# AST1060 register map
File version: 1.0
CPU: CM4 r0p1, little endian, MPU, FPU, 4 interrupt priority bits, 256 interrupts
Registers are 32-bit, read-write, reset 0x0 unless marked. A register's access mark holds for its fields unless they carry their own. Offsets are from the block's base; [hi:lo] are bit positions; {n}, {i} and the like mark numbered series.

## scu
Base 0x7E6E2000
0x00 SCU000 — Protection Key Register
  [31:0] ProtKey — Protection Key
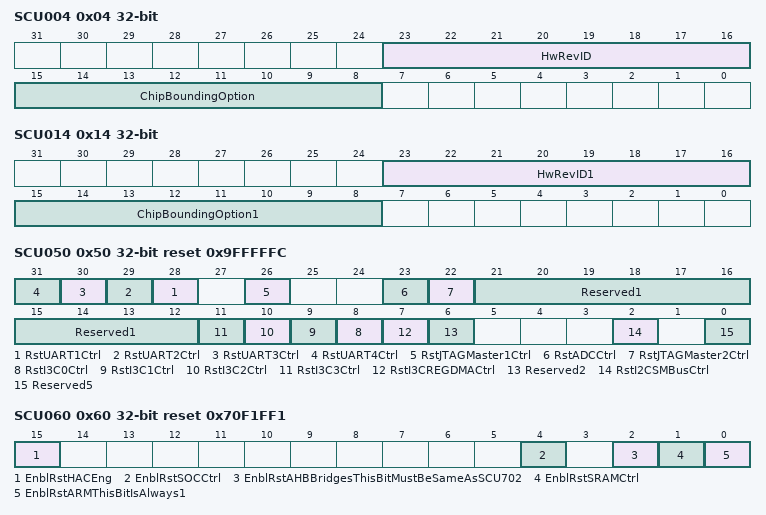
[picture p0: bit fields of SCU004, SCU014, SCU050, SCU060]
0x04 SCU004 — Silicon Revision ID Register
  [23:16] HwRevID ro — Hardware Revision ID
  [15:8] ChipBoundingOption ro
0x10 SCU010 — Protection Key Register 2
  [31:0] ThisRegIsDesignedToProtectSCURegFromUnpredictableUpdates — This register is designed to protect SCU registers from unpredictable updates,
0x14 SCU014 — Silicon Revision ID Register
  [23:16] HwRevID1 ro — Hardware Revision ID
  [15:8] ChipBoundingOption1 ro — Chip bounding option
0x40 SCU040 reset 0xFFC3FED8 — System Reset Control Register
  [0] EnblRstSRAMCtrlWhenFullChipWDResetOccur — Enable reset SRAM controller when full chip Watchdog reset occur
0x44 SCU044 — System Reset Control Clear Register 2
  [31:0] SCU040SysRstCtrlClearReg — SCU040 System Reset Control Clear Register
0x50 SCU050 reset 0x9FFFFFC (reset mask 0xFCC00F84) — System Reset Control Register Set 2
  [n+27] RstUART{n}Ctrl (n=1..4) — Reset UART{n} controller
  [26] RstJTAGMaster1Ctrl — Reset JTAG Master 1 controller
  [23] RstADCCtrl — Reset ADC controller
  [22] RstJTAGMaster2Ctrl — Reset JTAG Master 2 controller
  [21:12] Reserved1 — Reserved, must keep at value all "1"
  [n+8] RstI3C{n}Ctrl (n=0..3) — Reset I3C{n} controller
  [7] RstI3CREGDMACtrl — Reset I3C REG/DMA controller
  [6] Reserved2 — Reserved, must keep at value "1"
  [2] RstI2CSMBusCtrl — Reset I2C/SMBus controller
  [0] Reserved5 — Reserved, must keep at value "1"
0x54 SCU054 — System Reset Control Clear Register 2
  [31:0] SCU050SysRstCtrlClearReg2 — SCU050 System Reset Control Clear Register 2
0x60 SCU060 reset 0x70F1FF1 — EXTRST\# Reset Selection
  [15] EnblRstHACEng — Enable reset HAC engine
  [4] EnblRstSOCCtrl — Enable reset SOC controller
  [2] EnblRstAHBBridgesThisBitMustBeSameAsSCU702 — Enable reset AHB bridges. This bit must be same as SCU70[2].
  [1] EnblRstSRAMCtrl — Enable reset SRAM controller
  [0] EnblRstARMThisBitIsAlways1 ro — Enable reset ARM. This bit is always 1.
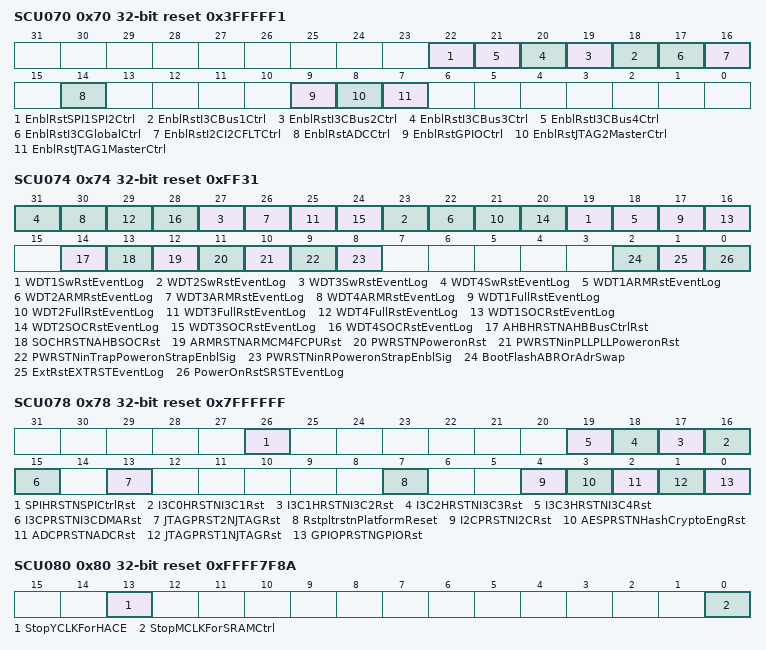
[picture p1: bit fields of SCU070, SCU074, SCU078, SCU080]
0x70 SCU070 reset 0x3FFFFF1 — EXTRST\# Reset Selection
  [22] EnblRstSPI1SPI2Ctrl — Enable reset SPI1/SPI2 controller
  [n+17] EnblRstI3CBus{n}Ctrl (n=1..4) — Enable reset I3C bus{n} controller
  [17] EnblRstI3CGlobalCtrl — Enable reset I3C Global controller
  [16] EnblRstI2CI2CFLTCtrl — Enable reset I2C/I2CFLT controller
  [14] EnblRstADCCtrl — Enable reset ADC controller
  [9] EnblRstGPIOCtrl — Enable reset GPIO controller
  [8] EnblRstJTAG2MasterCtrl — Enable reset JTAG #2 master controller
  [7] EnblRstJTAG1MasterCtrl — Enable reset JTAG #1 master controller
0x74 SCU074 reset 0xFF31 — System Reset Event Log Register Set 2-1
  [4n+15] WDT{n}SwRstEventLog (n=1..4) — WDT{n} Software Reset event log
  [4n+14] WDT{n}ARMRstEventLog (n=1..4) — WDT{n} ARM Reset event log
  [4n+13] WDT{n}FullRstEventLog (n=1..4) — WDT{n} Full Reset event log
  [4n+12] WDT{n}SOCRstEventLog (n=1..4) — WDT{n} SOC Reset event log
  [14] AHBHRSTNAHBBusCtrlRst — Reset event log -- AHB_HRST_N AHB Bus Controller reset
  [13] SOCHRSTNAHBSOCRst — Reset event log -- SOC_HRST_N AHB SOC reset
  [12] ARMRSTNARMCM4FCPURst — Reset event log -- ARMRST_N ARM CM4F CPU reset
  [11] PWRSTNPoweronRst — Reset event log -- PWRST_N Power-on reset
  [10] PWRSTNinPLLPLLPoweronRst — Reset event log -- PWRSTNinPLL PLL power-on reset
  [9] PWRSTNinTrapPoweronStrapEnblSig — Reset event log -- PWRSTNinTrap Power-on strap enable signal
  [8] PWRSTNinRPoweronStrapEnblSig — Reset event log -- PWRSTNinR Power-on strap enable signal
  [2] BootFlashABROrAdrSwap — Boot flash reset event log -- ABR or AdrSwap
  [1] ExtRstEXTRSTEventLog — External reset EXTRST# event log
  [0] PowerOnRstSRSTEventLog — Power on reset SRST# event log
0x78 SCU078 reset 0x7FFFFFF — System Reset Event Log Register Set 2-2
  [26] SPIHRSTNSPICtrlRst — Reset event log -- SPI_HRST_N SPI Controller reset
  [n+16] I3C{n}HRSTNI3C{n+1}Rst (n=0..3) — Reset event log -- I3C{n}_HRST_N I3C #{n+1} reset
  [15] I3CPRSTNI3CDMARst — Reset event log -- I3C_PRST_N I3C DMA reset
  [13] JTAGPRST2NJTAGRst — Reset event log -- JTAG_PRST#2_N JTAG reset
  [7] RstpltrstnPlatformReset — Reset event log -- rstpltrstn Platform Reset
  [4] I2CPRSTNI2CRst — Reset event log -- I2C_PRST_N I2C reset
  [3] AESPRSTNHashCryptoEngRst — Reset event log -- AES_PRST_N Hash crypto engine reset
  [2] ADCPRSTNADCRst — Reset event log -- ADC_PRST_N ADC reset
  [1] JTAGPRST1NJTAGRst — Reset event log -- JTAG_PRST#1_N JTAG reset
  [0] GPIOPRSTNGPIORst — Reset event log -- GPIO_PRST_N GPIO reset
0x80 SCU080 reset 0xFFFF7F8A — Clock Stop Control Register
  [13] StopYCLKForHACE
  [0] StopMCLKForSRAMCtrl — Stop MCLK (For SRAM Controller)
0x84 SCU084 — Clock Stop Control Clear Register
  [31:0] SCU080ClkStopCtrlClearReg — SCU080 Clock Stop Control Clear Register
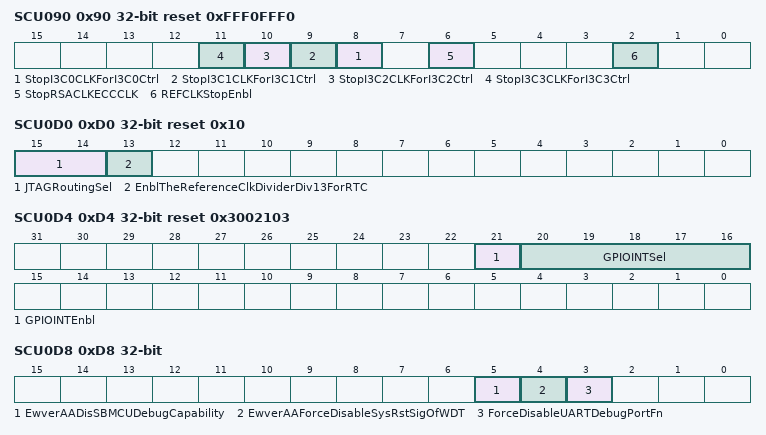
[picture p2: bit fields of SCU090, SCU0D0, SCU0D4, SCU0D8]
0x90 SCU090 reset 0xFFF0FFF0 — Clock Stop Control Register Set 2
  [n+8] StopI3C{n}CLKForI3C{n}Ctrl (n=0..3) — Stop I3C{n}CLK (for I3C{n} Controller)
  [6] StopRSACLKECCCLK
  [2] REFCLKStopEnbl — REFCLK Stop Enable
0x94 SCU094 — Clock Stop Control Clear Register Set 2
  [31:0] SCU090ClkStopCtrlClearRegSet2 — SCU090 Clock Stop Control Clear Register Set 2
0xD0 SCU0D0 reset 0x10 — Misc. 3 Control Register\label{SCUREG:MISC3
  [15:14] JTAGRoutingSel — JTAG routing selection
  [13] EnblTheReferenceClkDividerDiv13ForRTC — Enable the reference clock divider (div13) for RTC
0xD4 SCU0D4 reset 0x3002103 — Misc. 4 Control Register\label{SCUREG:MISC4
  [21] GPIOINTEnbl — GPIO Interrupt Enable
  [20:16] GPIOINTSel — GPIO Interrupt Selection
0xD8 SCU0D8 — Debug Control Register 2
  [5] EwverAADisSBMCUDebugCapability — ewverAADisable SBMCU debug capability
  [4] EwverAAForceDisableSysRstSigOfWDT — ewverAAForce disable system reset signal of WDT
  [3] ForceDisableUARTDebugPortFn — Force disable UART debug port function
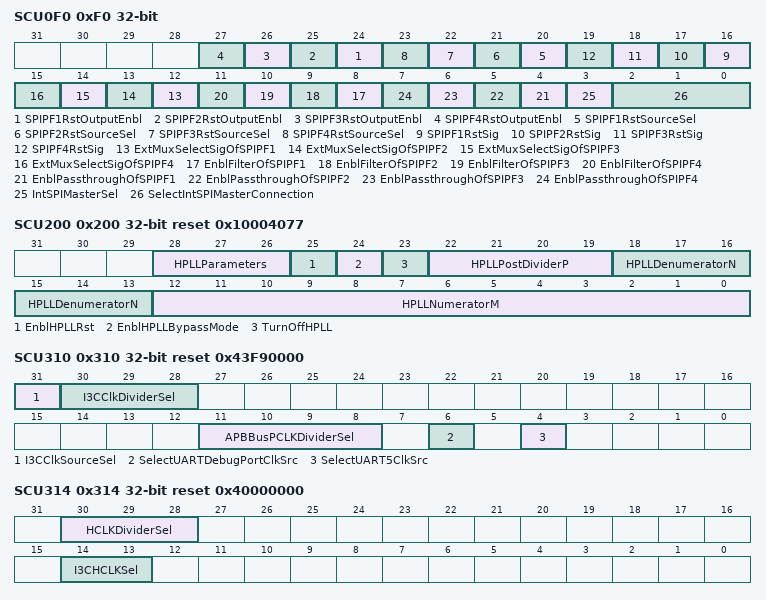
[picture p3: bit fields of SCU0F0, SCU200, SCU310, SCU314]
0xF0 SCU0F0 — QSPI Monitor Internal Mux Register
  [n+23] SPIPF{n}RstOutputEnbl (n=1..4) — SPI_PF{n} Reset Output Enable
  [n+19] SPIPF{n}RstSourceSel (n=1..4) — SPI_PF{n} Reset Source Selection
  [n+15] SPIPF{n}RstSig (n=1..4) — SPI_PF{n} Reset Signal
  [n+11] ExtMuxSelectSigOfSPIPF{n} (n=1..4) — External Mux Select Signal of SPI_PF{n}
  [n+7] EnblFilterOfSPIPF{n} (n=1..4) — Enable filter of SPI_PF{n}
  [n+3] EnblPassthroughOfSPIPF{n} (n=1..4) — Enable passthrough of SPI_PF{n}
  [3] IntSPIMasterSel — Internal SPI master selection
  [2:0] SelectIntSPIMasterConnection — Select internal SPI master connection
0x200 SCU200 reset 0x10004077 — H-PLL Parameter Register
  [28:26] HPLLParameters
  [25] EnblHPLLRst — Enable H-PLL reset
  [24] EnblHPLLBypassMode — Enable H-PLL bypass mode
  [23] TurnOffHPLL
  [22:19] HPLLPostDividerP
  [18:13] HPLLDenumeratorN
  [12:0] HPLLNumeratorM
0x204 SCU204 reset 0x31 — Extended H-PLL Parameter Register
  [11:0] HPLLBandwidthAdjustmentBit15 — 10]
0x310 SCU310 reset 0x43F90000 — Clock Selection Register Set 4
  [31] I3CClkSourceSel — I3C Clock Source selection
  [30:28] I3CClkDividerSel — I3C Clock divider selection
  [11:8] APBBusPCLKDividerSel — APB Bus PCLK divider selection
  [6] SelectUARTDebugPortClkSrc — Select UART debug port clock source
  [4] SelectUART5ClkSrc — Select UART5 clock source
0x314 SCU314 reset 0x40000000 — Clock Selection Register Set 5
  [30:28] HCLKDividerSel — HCLK divider selection
  [14:13] I3CHCLKSel — I3CHCLK selection
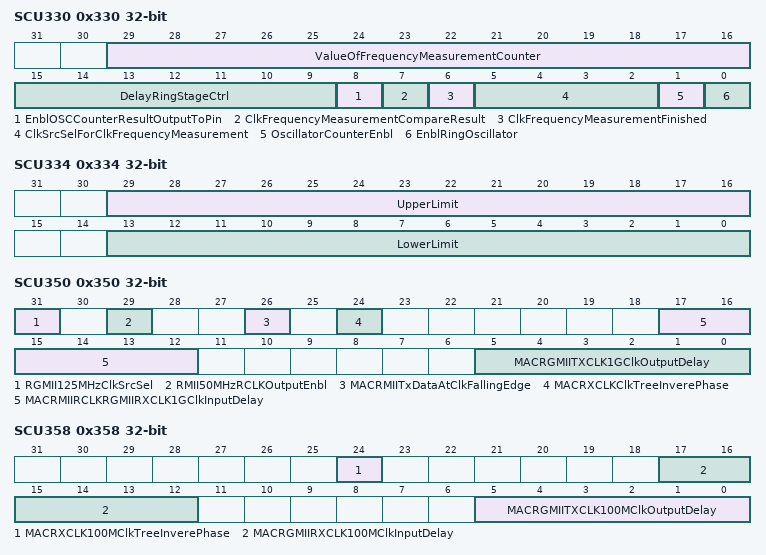
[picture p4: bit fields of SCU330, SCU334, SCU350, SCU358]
0x330 SCU330 — Frequency Counter Control Register
  [29:16] ValueOfFrequencyMeasurementCounter ro
  [15:9] DelayRingStageCtrl — Delay ring stage control
  [8] EnblOSCCounterResultOutputToPin — Enable OSC counter result output to pin
  [7] ClkFrequencyMeasurementCompareResult ro — Clock frequency measurement compare result
  [6] ClkFrequencyMeasurementFinished ro — Clock frequency measurement finished
  [5:2] ClkSrcSelForClkFrequencyMeasurement — Clock source selection for clock frequency measurement
  [1] OscillatorCounterEnbl — Oscillator Counter Enable
  [0] EnblRingOscillator — Enable Ring Oscillator
0x334 SCU334 — Frequency counter comparison range
  [29:16] UpperLimit, [13:0] LowerLimit
0x350 SCU350 — MAC Interface Clock Delay Setting
  [31] RGMII125MHzClkSrcSel — RGMII 125MHz clock source selection
  [29] RMII50MHzRCLKOutputEnbl — RMII 50MHz RCLK output enable
  [26] MACRMIITxDataAtClkFallingEdge — MAC RMII transmit data at clock falling edge
  [24] MACRXCLKClkTreeInverePhase — MAC RXCLK clock tree invere phase
  [17:12] MACRMIIRCLKRGMIIRXCLK1GClkInputDelay — MAC RMII_RCLK/RGMII_RXCLK (1G) clock input delay
  [5:0] MACRGMIITXCLK1GClkOutputDelay — MAC RGMII_TXCLK (1G) clock output delay
0x358 SCU358 — MAC Interface Clock Delay 100M Setting
  [24] MACRXCLK100MClkTreeInverePhase — MAC RXCLK 100M clock tree invere phase
  [17:12] MACRGMIIRXCLK100MClkInputDelay — MAC RGMII_RXCLK 100M clock input delay
  [5:0] MACRGMIITXCLK100MClkOutputDelay — MAC RGMII_TXCLK 100M clock output delay
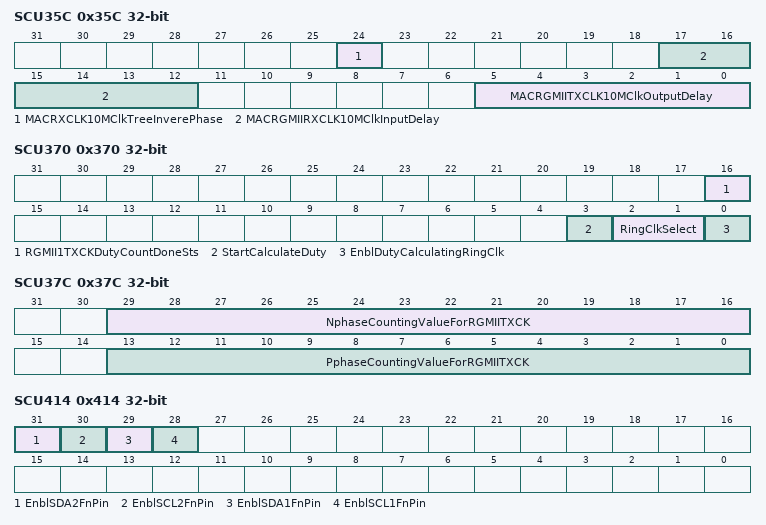
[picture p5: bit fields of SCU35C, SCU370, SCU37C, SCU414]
0x35C SCU35C — MAC Interface Clock Delay 10M Setting
  [24] MACRXCLK10MClkTreeInverePhase — MAC RXCLK 10M clock tree invere phase
  [17:12] MACRGMIIRXCLK10MClkInputDelay — MAC RGMII_RXCLK 10M clock input delay
  [5:0] MACRGMIITXCLK10MClkOutputDelay — MAC RGMII_TXCLK 10M clock output delay
0x370 SCU370 — Clock Duty Measurement Control
  [16] RGMII1TXCKDutyCountDoneSts ro — RGMII1TXCK Duty count done status
  [3] StartCalculateDuty
  [2:1] RingClkSelect — Ring clock select
  [0] EnblDutyCalculatingRingClk — Enable duty calculating ring clock
0x37C SCU37C — Clock Duty Measurement Result 2
  [29:16] NphaseCountingValueForRGMIITXCK ro, [13:0] PphaseCountingValueForRGMIITXCK ro
0x410 SCU410 reset not defined — Multi-function Pin Control \#1
0x414 SCU414 — Multi-function Pin Control \#2
  [31] EnblSDA2FnPin — Enable SDA2 function pin
  [30] EnblSCL2FnPin — Enable SCL2 function pin
  [29] EnblSDA1FnPin — Enable SDA1 function pin
  [28] EnblSCL1FnPin — Enable SCL1 function pin
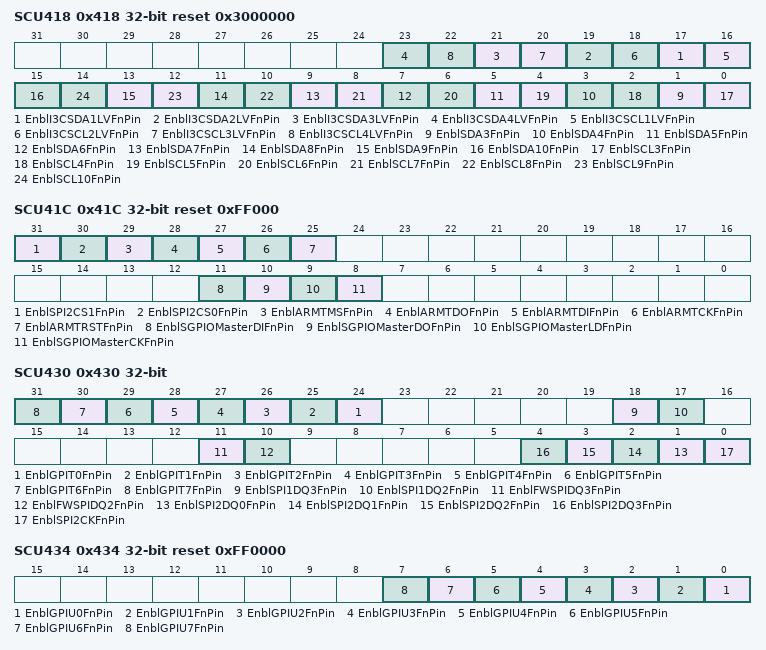
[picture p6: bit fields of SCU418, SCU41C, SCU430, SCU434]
0x418 SCU418 reset 0x3000000 — Multi-function Pin Control \#3
  [2n+15] EnblI3CSDA{n}LVFnPin (n=1..4) — Enable I3C SDA{n} LV function pin
  [2n+14] EnblI3CSCL{n}LVFnPin (n=1..4) — Enable I3C SCL{n} LV function pin
  [2n-5] EnblSDA{n}FnPin (n=3..10) — Enable SDA{n} function pin
  [2n-6] EnblSCL{n}FnPin (n=3..10) — Enable SCL{n} function pin
0x41C SCU41C reset 0xFF000 — Multi-function Pin Control \#4
  [31] EnblSPI2CS1FnPin — Enable SPI2CS1 function pin
  [30] EnblSPI2CS0FnPin — Enable SPI2CS0 function pin
  [29] EnblARMTMSFnPin — Enable ARM TMS function pin
  [28] EnblARMTDOFnPin — Enable ARM TDO function pin
  [27] EnblARMTDIFnPin — Enable ARM TDI function pin
  [26] EnblARMTCKFnPin — Enable ARM TCK function pin
  [25] EnblARMTRSTFnPin — Enable ARM TRST function pin
  [11] EnblSGPIOMasterDIFnPin — Enable SGPIO Master DI function pin
  [10] EnblSGPIOMasterDOFnPin — Enable SGPIO Master DO function pin
  [9] EnblSGPIOMasterLDFnPin — Enable SGPIO Master LD function pin
  [8] EnblSGPIOMasterCKFnPin — Enable SGPIO Master CK function pin
0x430 SCU430 — Multi-function Pin Control \#5
  [n+24] EnblGPIT{n}FnPin (n=0..7) — Enable GPIT{n} function pin
  [18] EnblSPI1DQ3FnPin — Enable SPI1DQ3 function pin
  [17] EnblSPI1DQ2FnPin — Enable SPI1DQ2 function pin
  [11] EnblFWSPIDQ3FnPin — Enable FWSPIDQ3 function pin
  [10] EnblFWSPIDQ2FnPin — Enable FWSPIDQ2 function pin
  [n+1] EnblSPI2DQ{n}FnPin (n=0..3) — Enable SPI2DQ{n} function pin
  [0] EnblSPI2CKFnPin — Enable SPI2CK function pin
0x434 SCU434 reset 0xFF0000 — Multi-function Pin Control \#6
  [n] EnblGPIU{n}FnPin (n=0..7) — Enable GPIU{n} function pin
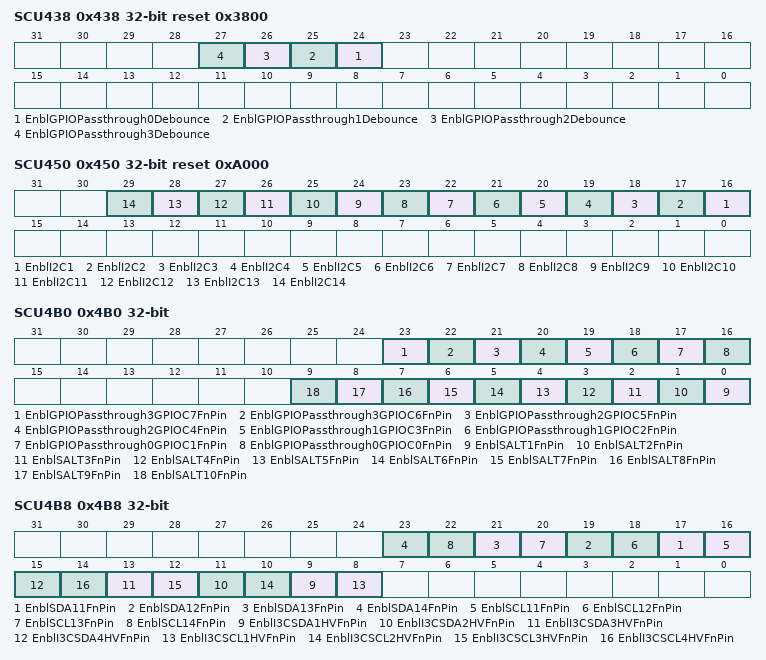
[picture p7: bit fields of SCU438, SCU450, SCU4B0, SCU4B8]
0x438 SCU438 reset 0x3800 — Multi-function Pin Control \#7
  [n+24] EnblGPIOPassthrough{n}Debounce (n=0..3) — Enable GPIO Passthrough {n} de-bounce
0x450 SCU450 reset 0xA000 — Multi-function Pin Control \#9
  [n+15] EnblI2C{n} (n=1..14) — Enable I2C{n}
0x454 SCU454 — Multi-function Pin Control \#10
  [20] EnblJTAGMasterRouting — Enable JTAG master routing
0x458 SCU458 reset 0x500 — Multi-function Pin Control \#11
  [20] VoltageOfGPION4N5N6N7O0O1O2O3
0x4B0 SCU4B0 — Multi-function Pin Control \#13
  [23] EnblGPIOPassthrough3GPIOC7FnPin — Enable GPIO Passthrough 3 (GPIOC7) function pin
  [22] EnblGPIOPassthrough3GPIOC6FnPin — Enable GPIO Passthrough 3 (GPIOC6) function pin
  [21] EnblGPIOPassthrough2GPIOC5FnPin — Enable GPIO Passthrough 2 (GPIOC5) function pin
  [20] EnblGPIOPassthrough2GPIOC4FnPin — Enable GPIO Passthrough 2 (GPIOC4) function pin
  [19] EnblGPIOPassthrough1GPIOC3FnPin — Enable GPIO Passthrough 1 (GPIOC3) function pin
  [18] EnblGPIOPassthrough1GPIOC2FnPin — Enable GPIO Passthrough 1 (GPIOC2) function pin
  [17] EnblGPIOPassthrough0GPIOC1FnPin — Enable GPIO Passthrough 0 (GPIOC1) function pin
  [16] EnblGPIOPassthrough0GPIOC0FnPin — Enable GPIO Passthrough 0 (GPIOC0) function pin
  [n-1] EnblSALT{n}FnPin (n=1..10) — Enable SALT{n} function pin
0x4B4 SCU4B4 reset not defined — Multi-function Pin Control \#14
0x4B8 SCU4B8 — Multi-function Pin Control \#15
  [2n-5] EnblSDA{n}FnPin (n=11..14) — Enable SDA{n} function pin
  [2n-6] EnblSCL{n}FnPin (n=11..14) — Enable SCL{n} function pin
  [2n+7] EnblI3CSDA{n}HVFnPin (n=1..4) — Enable I3C SDA{n} HV function pin
  [2n+6] EnblI3CSCL{n}HVFnPin (n=1..4) — Enable I3C SCL{n} HV function pin
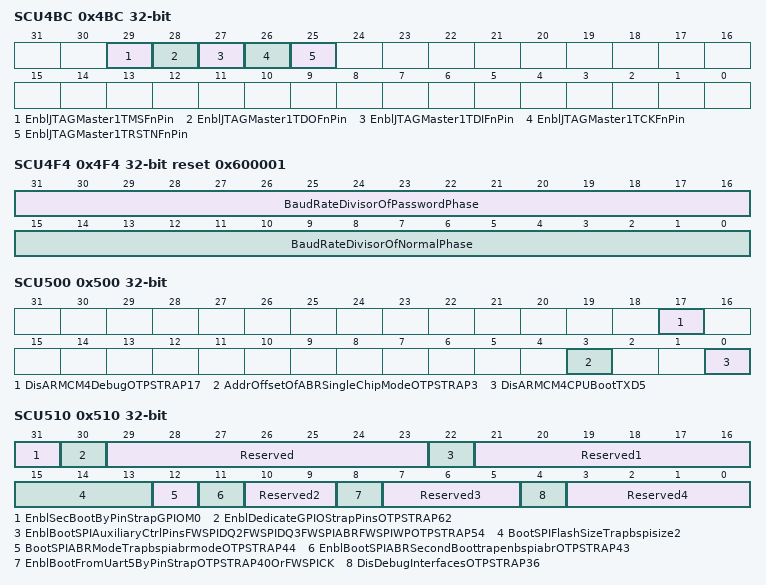
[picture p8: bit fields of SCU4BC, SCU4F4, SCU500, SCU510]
0x4BC SCU4BC — Multi-function Pin Control \#16
  [29] EnblJTAGMaster1TMSFnPin — Enable JTAG Master #1 TMS function pin
  [28] EnblJTAGMaster1TDOFnPin — Enable JTAG Master #1 TDO function pin
  [27] EnblJTAGMaster1TDIFnPin — Enable JTAG Master #1 TDI function pin
  [26] EnblJTAGMaster1TCKFnPin — Enable JTAG Master #1 TCK function pin
  [25] EnblJTAGMaster1TRSTNFnPin — Enable JTAG Master #1 TRSTN function pin
0x4D4 SCU4D4 reset not defined — Multi-function Pin Control \#18
0x4D8 SCU4D8 reset not defined — Multi-function Pin Control \#19
0x4F4 SCU4F4 reset 0x600001 — UART Debug interface Baud Rate Control
  [31:16] BaudRateDivisorOfPasswordPhase, [15:0] BaudRateDivisorOfNormalPhase
0x500 SCU500 — Hardware Strap1 Register\label{SCUREG:HWTRAPL
  [17] DisARMCM4DebugOTPSTRAP17 — Disable ARM CM4 debug (hlinkOTPSTRAP[17])
  [3] AddrOffsetOfABRSingleChipModeOTPSTRAP3 — Address Offset of ABR Single Chip Mode(hlinkOTPSTRAP[3])
  [0] DisARMCM4CPUBootTXD5 — Disable ARM CM4 CPU boot (TXD5)
0x504 SCU504 — Hardware Strap1 Clear Register
  [31:0] SCU500HwStrap1ClearReg — SCU500 Hardware Strap1 Clear Register
0x508 SCU508 reset 0x40080000 — Hardware Strap1 Protect Register
  [31:0] SCU500WrProtBitCtrl — SCU500 Write Protection Bit Control
0x510 SCU510 — Hardware Strap2 Register\label{SCUREG:HWTRAPH
  [31] EnblSecBootByPinStrapGPIOM0 — Enable Secure Boot by Pin Strap (GPIOM0)
  [30] EnblDedicateGPIOStrapPinsOTPSTRAP62 — Enable Dedicate GPIO Strap Pins (hlinkOTPSTRAP[62])
  [29:23] Reserved — 57])
  [22] EnblBootSPIAuxiliaryCtrlPinsFWSPIDQ2FWSPIDQ3FWSPIABRFWSPIWPOTPSTRAP54 — Enable boot SPI auxiliary control pins FWSPIDQ2, FWSPIDQ3, FWSPIABR#, FWSPIWP# (hlinkOTPSTRAP[54])
  [21:16] Reserved1 — 48])
  [15:13] BootSPIFlashSizeTrapbspisize2 — 0]) (hlinkOTPSTRAP[47:45], FWSPICK, GPION2,GPION0)
  [12] BootSPIABRModeTrapbspiabrmodeOTPSTRAP44 — Boot SPI ABR Mode (trap_bspi_abrmode) (hlinkOTPSTRAP[44])
  [11] EnblBootSPIABRSecondBoottrapenbspiabrOTPSTRAP43 — Enable boot SPI ABR (second boot)(trap_en_bspiabr) (hlinkOTPSTRAP[43])
  [10:9] Reserved2 — 41])
  [8] EnblBootFromUart5ByPinStrapOTPSTRAP40OrFWSPICK — Enable Boot from Uart5 by Pin Strap (hlinkOTPSTRAP[40] or FWSPICK)
  [7:5] Reserved3 — 37])
  [4] DisDebugInterfacesOTPSTRAP36 — Disable Debug Interfaces (hlinkOTPSTRAP[36])
  [3:0] Reserved4 — 32])
0x514 SCU514 — Hardware Strap2 Clear Register
  [31:0] SCU510HwStrap2ClearReg — SCU510 Hardware Strap2 Clear Register
0x518 SCU518 reset 0x10 — Hardware Strap2 Protect Register
  [31:0] SCU510WrProtBitCtrl — SCU510 Write Protection Bit Control
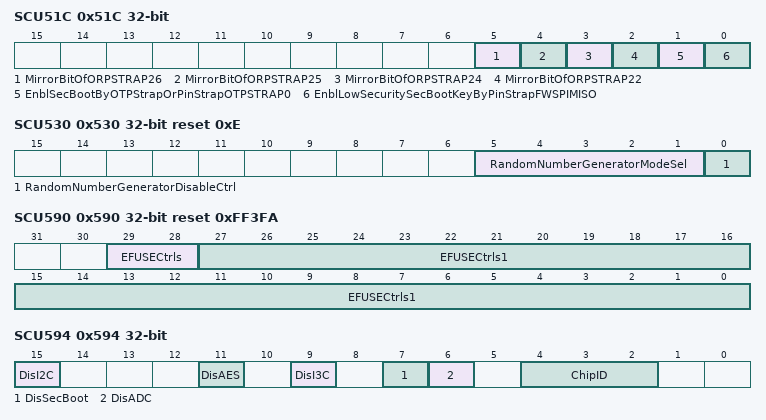
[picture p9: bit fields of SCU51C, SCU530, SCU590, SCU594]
0x51C SCU51C — Hardware Pin Strap Register\label{SCUREG:HWTRAPHRO
  [5] MirrorBitOfORPSTRAP26
  [4] MirrorBitOfORPSTRAP25
  [3] MirrorBitOfORPSTRAP24
  [2] MirrorBitOfORPSTRAP22
  [1] EnblSecBootByOTPStrapOrPinStrapOTPSTRAP0 — Enable Secure Boot by OTP Strap or Pin Strap (hlinkOTPSTRAP[0])
  [0] EnblLowSecuritySecBootKeyByPinStrapFWSPIMISO — Enable Low Security Secure Boot Key by Pin Strap (FWSPIMISO)
0x530 SCU530 reset 0xE — Random Number Generator 2 Control
  [5:1] RandomNumberGeneratorModeSel — Random number generator mode selection
  [0] RandomNumberGeneratorDisableCtrl — Random number generator disable control
0x534 SCU534 — Random Number Generator 2 Data Output
  [31:0] RandomNumberData ro
0x590 SCU590 reset 0xFF3FA — EFUSE Control
  [29:28] EFUSECtrls ro — EFUSE Controls
  [27:0] EFUSECtrls1 — EFUSE Controls
0x594 SCU594 — EFUSE Data Register
  [15] DisI2C ro — Disable I2C
  [11] DisAES ro — Disable AES
  [9] DisI3C ro — Disable I3C
  [7] DisSecBoot ro — Disable Secure Boot
  [6] DisADC ro — Disable ADC
  [4:2] ChipID ro
0x5B0 SCU5B0 — Chip Unique ID 0
  [31:0] ChipUniqueIDBit63 ro — 0] read back
0x5B4 SCU5B4 — Chip Unique ID 1
  [31:0] ChipUniqueIDBit631 ro — 0] read back
0x5B8 SCU5B8 — Reserved Read Only ID 0
  [31:0] Reserved ro — 0] read back
0x5BC SCU5BC — Reserved Read Only ID 1
  [31:0] Reserved1 ro — 0] read back
0x5D0 SCU5D0 — Reserved Read Only ID 2
  [31:0] Reserved2 ro — 0] read back
0x5D4 SCU5D4 — Reserved Read Only ID 3
  [31:0] Reserved3 ro — 0] read back
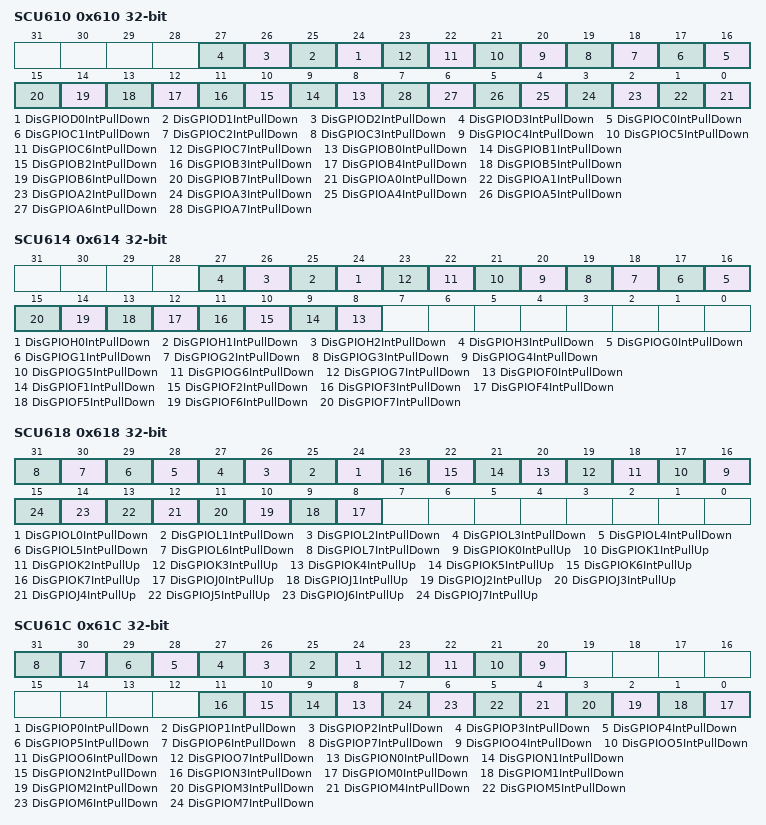
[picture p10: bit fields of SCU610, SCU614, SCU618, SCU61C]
0x610 SCU610 — Disable GPIO Internal Pull-Down \#0
  [n+24] DisGPIOD{n}IntPullDown (n=0..3) — Disable GPIOD{n} Internal Pull-Down
  [n+16] DisGPIOC{n}IntPullDown (n=0..7) — Disable GPIOC{n} Internal Pull-Down
  [n+8] DisGPIOB{n}IntPullDown (n=0..7) — Disable GPIOB{n} Internal Pull-Down
  [n] DisGPIOA{n}IntPullDown (n=0..7) — Disable GPIOA{n} Internal Pull-Down
0x614 SCU614 — Disable GPIO Internal Pull-Down \#1
  [n+24] DisGPIOH{n}IntPullDown (n=0..3) — Disable GPIOH{n} Internal Pull-Down
  [n+16] DisGPIOG{n}IntPullDown (n=0..7) — Disable GPIOG{n} Internal Pull-Down
  [n+8] DisGPIOF{n}IntPullDown (n=0..7) — Disable GPIOF{n} Internal Pull-Down
0x618 SCU618 — Disable GPIO Internal Pull-Down \#2
  [n+24] DisGPIOL{n}IntPullDown (n=0..7) — Disable GPIOL{n} Internal Pull-Down
  [n+16] DisGPIOK{n}IntPullUp (n=0..7) — Disable GPIOK{n} Internal Pull-Up
  [n+8] DisGPIOJ{n}IntPullUp (n=0..7) — Disable GPIOJ{n} Internal Pull-Up
0x61C SCU61C — Disable GPIO Internal Pull-Down \#3
  [n+24] DisGPIOP{n}IntPullDown (n=0..7) — Disable GPIOP{n} Internal Pull-Down
  [n+16] DisGPIOO{n}IntPullDown (n=4..7) — Disable GPIOO{n} Internal Pull-Down
  [n+8] DisGPION{n}IntPullDown (n=0..3) — Disable GPION{n} Internal Pull-Down
  [n] DisGPIOM{n}IntPullDown (n=0..7) — Disable GPIOM{n} Internal Pull-Down
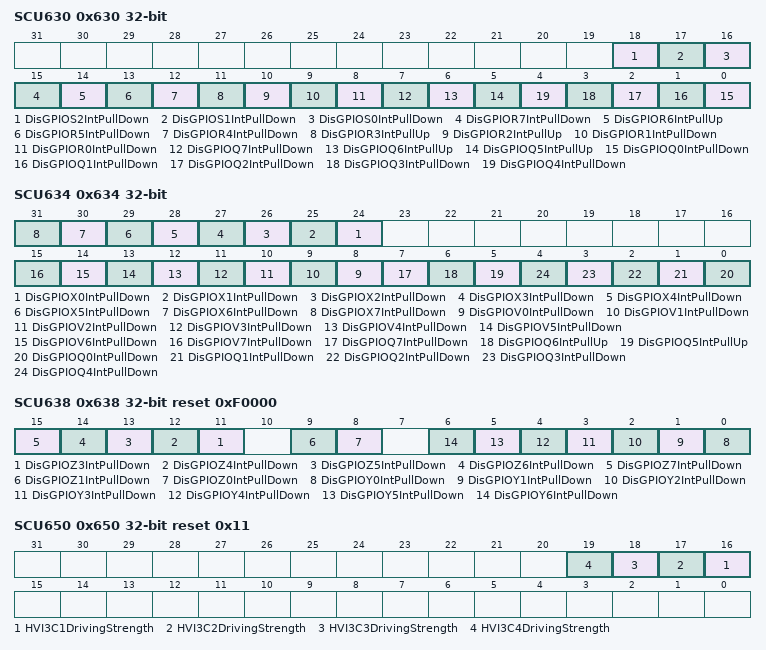
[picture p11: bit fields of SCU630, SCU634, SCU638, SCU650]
0x630 SCU630 — Disable GPIO Internal Pull-Down \#4
  [18] DisGPIOS2IntPullDown — Disable GPIOS2 Internal Pull-Down
  [17] DisGPIOS1IntPullDown — Disable GPIOS1 Internal Pull-Down
  [16] DisGPIOS0IntPullDown — Disable GPIOS0 Internal Pull-Down
  [15] DisGPIOR7IntPullDown — Disable GPIOR7 Internal Pull-Down
  [14] DisGPIOR6IntPullUp — Disable GPIOR6 Internal Pull-Up
  [13] DisGPIOR5IntPullDown — Disable GPIOR5 Internal Pull-Down
  [12] DisGPIOR4IntPullDown — Disable GPIOR4 Internal Pull-Down
  [11] DisGPIOR3IntPullUp — Disable GPIOR3 Internal Pull-Up
  [10] DisGPIOR2IntPullUp — Disable GPIOR2 Internal Pull-Up
  [9] DisGPIOR1IntPullDown — Disable GPIOR1 Internal Pull-Down
  [8] DisGPIOR0IntPullDown — Disable GPIOR0 Internal Pull-Down
  [7] DisGPIOQ7IntPullDown — Disable GPIOQ7 Internal Pull-Down
  [6] DisGPIOQ6IntPullUp — Disable GPIOQ6 Internal Pull-Up
  [5] DisGPIOQ5IntPullUp — Disable GPIOQ5 Internal Pull-Up
  [n] DisGPIOQ{n}IntPullDown (n=0..4) — Disable GPIOQ{n} Internal Pull-Down
0x634 SCU634 — Disable GPIO Internal Pull-Down \#5
  [n+24] DisGPIOX{n}IntPullDown (n=0..7) — Disable GPIOX{n} Internal Pull-Down
  [n+8] DisGPIOV{n}IntPullDown (n=0..7) — Disable GPIOV{n} Internal Pull-Down
  [7] DisGPIOQ7IntPullDown — Disable GPIOQ7 Internal Pull-Down
  [6] DisGPIOQ6IntPullUp — Disable GPIOQ6 Internal Pull-Up
  [5] DisGPIOQ5IntPullUp — Disable GPIOQ5 Internal Pull-Up
  [n] DisGPIOQ{n}IntPullDown (n=0..4) — Disable GPIOQ{n} Internal Pull-Down
0x638 SCU638 reset 0xF0000 — Disable GPIO Internal Pull-Down \#6
  [n+8] DisGPIOZ{n}IntPullDown (n=3..7) — Disable GPIOZ{n} Internal Pull-Down
  [9] DisGPIOZ1IntPullDown — Disable GPIOZ1 Internal Pull-Down
  [8] DisGPIOZ0IntPullDown — Disable GPIOZ0 Internal Pull-Down
  [n] DisGPIOY{n}IntPullDown (n=0..6) — Disable GPIOY{n} Internal Pull-Down
0x650 SCU650 reset 0x11 (reset mask 0x0) — IO Driving Strength
  [n+15] HVI3C{n}DrivingStrength (n=1..4)
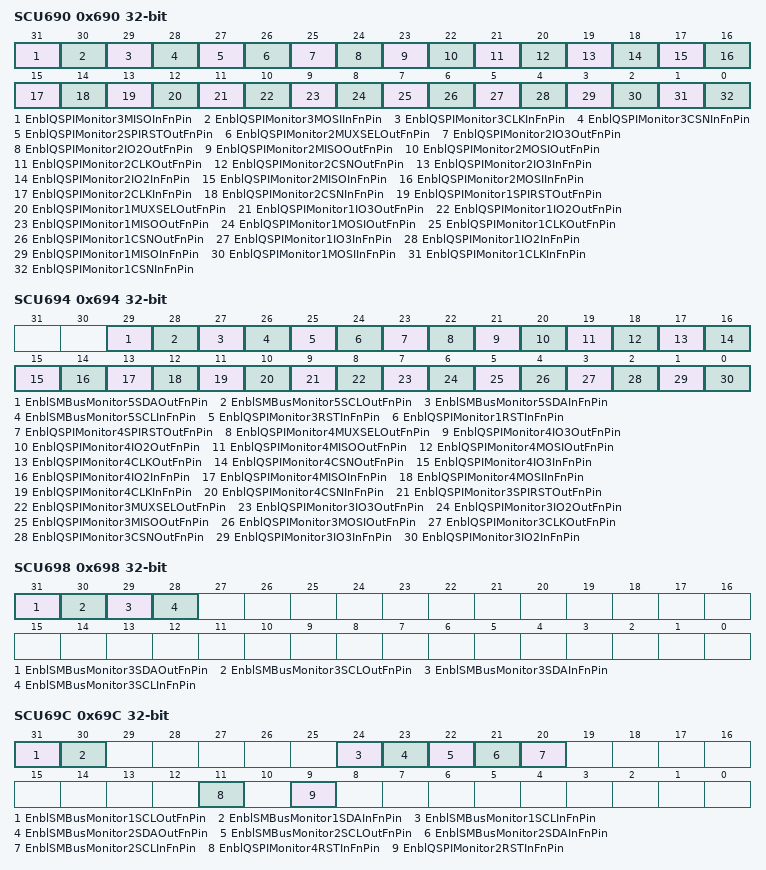
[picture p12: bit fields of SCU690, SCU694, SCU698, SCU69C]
0x690 SCU690 — Multi-function Pin Control \#21
  [31] EnblQSPIMonitor3MISOInFnPin — Enable QSPI Monitor 3 MISO In function pin
  [30] EnblQSPIMonitor3MOSIInFnPin — Enable QSPI Monitor 3 MOSI In function pin
  [29] EnblQSPIMonitor3CLKInFnPin — Enable QSPI Monitor 3 CLK In function pin
  [28] EnblQSPIMonitor3CSNInFnPin — Enable QSPI Monitor 3 CSN In function pin
  [27] EnblQSPIMonitor2SPIRSTOutFnPin — Enable QSPI Monitor 2 SPIRST Out function pin
  [26] EnblQSPIMonitor2MUXSELOutFnPin — Enable QSPI Monitor 2 MUXSEL Out function pin
  [25] EnblQSPIMonitor2IO3OutFnPin — Enable QSPI Monitor 2 IO3 Out function pin
  [24] EnblQSPIMonitor2IO2OutFnPin — Enable QSPI Monitor 2 IO2 Out function pin
  [23] EnblQSPIMonitor2MISOOutFnPin — Enable QSPI Monitor 2 MISO Out function pin
  [22] EnblQSPIMonitor2MOSIOutFnPin — Enable QSPI Monitor 2 MOSI Out function pin
  [21] EnblQSPIMonitor2CLKOutFnPin — Enable QSPI Monitor 2 CLK Out function pin
  [20] EnblQSPIMonitor2CSNOutFnPin — Enable QSPI Monitor 2 CSN Out function pin
  [19] EnblQSPIMonitor2IO3InFnPin — Enable QSPI Monitor 2 IO3 In function pin
  [18] EnblQSPIMonitor2IO2InFnPin — Enable QSPI Monitor 2 IO2 In function pin
  [17] EnblQSPIMonitor2MISOInFnPin — Enable QSPI Monitor 2 MISO In function pin
  [16] EnblQSPIMonitor2MOSIInFnPin — Enable QSPI Monitor 2 MOSI In function pin
  [15] EnblQSPIMonitor2CLKInFnPin — Enable QSPI Monitor 2 CLK In function pin
  [14] EnblQSPIMonitor2CSNInFnPin — Enable QSPI Monitor 2 CSN In function pin
  [13] EnblQSPIMonitor1SPIRSTOutFnPin — Enable QSPI Monitor 1 SPIRST Out function pin
  [12] EnblQSPIMonitor1MUXSELOutFnPin — Enable QSPI Monitor 1 MUXSEL Out function pin
  [11] EnblQSPIMonitor1IO3OutFnPin — Enable QSPI Monitor 1 IO3 Out function pin
  [10] EnblQSPIMonitor1IO2OutFnPin — Enable QSPI Monitor 1 IO2 Out function pin
  [9] EnblQSPIMonitor1MISOOutFnPin — Enable QSPI Monitor 1 MISO Out function pin
  [8] EnblQSPIMonitor1MOSIOutFnPin — Enable QSPI Monitor 1 MOSI Out function pin
  [7] EnblQSPIMonitor1CLKOutFnPin — Enable QSPI Monitor 1 CLK Out function pin
  [6] EnblQSPIMonitor1CSNOutFnPin — Enable QSPI Monitor 1 CSN Out function pin
  [5] EnblQSPIMonitor1IO3InFnPin — Enable QSPI Monitor 1 IO3 In function pin
  [4] EnblQSPIMonitor1IO2InFnPin — Enable QSPI Monitor 1 IO2 In function pin
  [3] EnblQSPIMonitor1MISOInFnPin — Enable QSPI Monitor 1 MISO In function pin
  [2] EnblQSPIMonitor1MOSIInFnPin — Enable QSPI Monitor 1 MOSI In function pin
  [1] EnblQSPIMonitor1CLKInFnPin — Enable QSPI Monitor 1 CLK In function pin
  [0] EnblQSPIMonitor1CSNInFnPin — Enable QSPI Monitor 1 CSN In function pin
0x694 SCU694 — Multi-function Pin Control \#22
  [29] EnblSMBusMonitor5SDAOutFnPin — Enable SMBus Monitor 5 SDA Out function pin
  [28] EnblSMBusMonitor5SCLOutFnPin — Enable SMBus Monitor 5 SCL Out function pin
  [27] EnblSMBusMonitor5SDAInFnPin — Enable SMBus Monitor 5 SDA In function pin
  [26] EnblSMBusMonitor5SCLInFnPin — Enable SMBus Monitor 5 SCL In function pin
  [25] EnblQSPIMonitor3RSTInFnPin — Enable QSPI Monitor 3 RST In function pin
  [24] EnblQSPIMonitor1RSTInFnPin — Enable QSPI Monitor 1 RST In function pin
  [23] EnblQSPIMonitor4SPIRSTOutFnPin — Enable QSPI Monitor 4 SPIRST Out function pin
  [22] EnblQSPIMonitor4MUXSELOutFnPin — Enable QSPI Monitor 4 MUXSEL Out function pin
  [21] EnblQSPIMonitor4IO3OutFnPin — Enable QSPI Monitor 4 IO3 Out function pin
  [20] EnblQSPIMonitor4IO2OutFnPin — Enable QSPI Monitor 4 IO2 Out function pin
  [19] EnblQSPIMonitor4MISOOutFnPin — Enable QSPI Monitor 4 MISO Out function pin
  [18] EnblQSPIMonitor4MOSIOutFnPin — Enable QSPI Monitor 4 MOSI Out function pin
  [17] EnblQSPIMonitor4CLKOutFnPin — Enable QSPI Monitor 4 CLK Out function pin
  [16] EnblQSPIMonitor4CSNOutFnPin — Enable QSPI Monitor 4 CSN Out function pin
  [15] EnblQSPIMonitor4IO3InFnPin — Enable QSPI Monitor 4 IO3 In function pin
  [14] EnblQSPIMonitor4IO2InFnPin — Enable QSPI Monitor 4 IO2 In function pin
  [13] EnblQSPIMonitor4MISOInFnPin — Enable QSPI Monitor 4 MISO In function pin
  [12] EnblQSPIMonitor4MOSIInFnPin — Enable QSPI Monitor 4 MOSI In function pin
  [11] EnblQSPIMonitor4CLKInFnPin — Enable QSPI Monitor 4 CLK In function pin
  [10] EnblQSPIMonitor4CSNInFnPin — Enable QSPI Monitor 4 CSN In function pin
  [9] EnblQSPIMonitor3SPIRSTOutFnPin — Enable QSPI Monitor 3 SPIRST Out function pin
  [8] EnblQSPIMonitor3MUXSELOutFnPin — Enable QSPI Monitor 3 MUXSEL Out function pin
  [7] EnblQSPIMonitor3IO3OutFnPin — Enable QSPI Monitor 3 IO3 Out function pin
  [6] EnblQSPIMonitor3IO2OutFnPin — Enable QSPI Monitor 3 IO2 Out function pin
  [5] EnblQSPIMonitor3MISOOutFnPin — Enable QSPI Monitor 3 MISO Out function pin
  [4] EnblQSPIMonitor3MOSIOutFnPin — Enable QSPI Monitor 3 MOSI Out function pin
  [3] EnblQSPIMonitor3CLKOutFnPin — Enable QSPI Monitor 3 CLK Out function pin
  [2] EnblQSPIMonitor3CSNOutFnPin — Enable QSPI Monitor 3 CSN Out function pin
  [1] EnblQSPIMonitor3IO3InFnPin — Enable QSPI Monitor 3 IO3 In function pin
  [0] EnblQSPIMonitor3IO2InFnPin — Enable QSPI Monitor 3 IO2 In function pin
0x698 SCU698 — Multi-function Pin Control \#23
  [31] EnblSMBusMonitor3SDAOutFnPin — Enable SMBus Monitor 3 SDA Out function pin
  [30] EnblSMBusMonitor3SCLOutFnPin — Enable SMBus Monitor 3 SCL Out function pin
  [29] EnblSMBusMonitor3SDAInFnPin — Enable SMBus Monitor 3 SDA In function pin
  [28] EnblSMBusMonitor3SCLInFnPin — Enable SMBus Monitor 3 SCL In function pin
0x69C SCU69C — Multi-function Pin Control \#24
  [31] EnblSMBusMonitor1SCLOutFnPin — Enable SMBus Monitor 1 SCL Out function pin
  [30] EnblSMBusMonitor1SDAInFnPin — Enable SMBus Monitor 1 SDA In function pin
  [24] EnblSMBusMonitor1SCLInFnPin — Enable SMBus Monitor 1 SCL In function pin
  [23] EnblSMBusMonitor2SDAOutFnPin — Enable SMBus Monitor 2 SDA Out function pin
  [22] EnblSMBusMonitor2SCLOutFnPin — Enable SMBus Monitor 2 SCL Out function pin
  [21] EnblSMBusMonitor2SDAInFnPin — Enable SMBus Monitor 2 SDA In function pin
  [20] EnblSMBusMonitor2SCLInFnPin — Enable SMBus Monitor 2 SCL In function pin
  [11] EnblQSPIMonitor4RSTInFnPin — Enable QSPI Monitor 4 RST In function pin
  [9] EnblQSPIMonitor2RSTInFnPin — Enable QSPI Monitor 2 RST In function pin
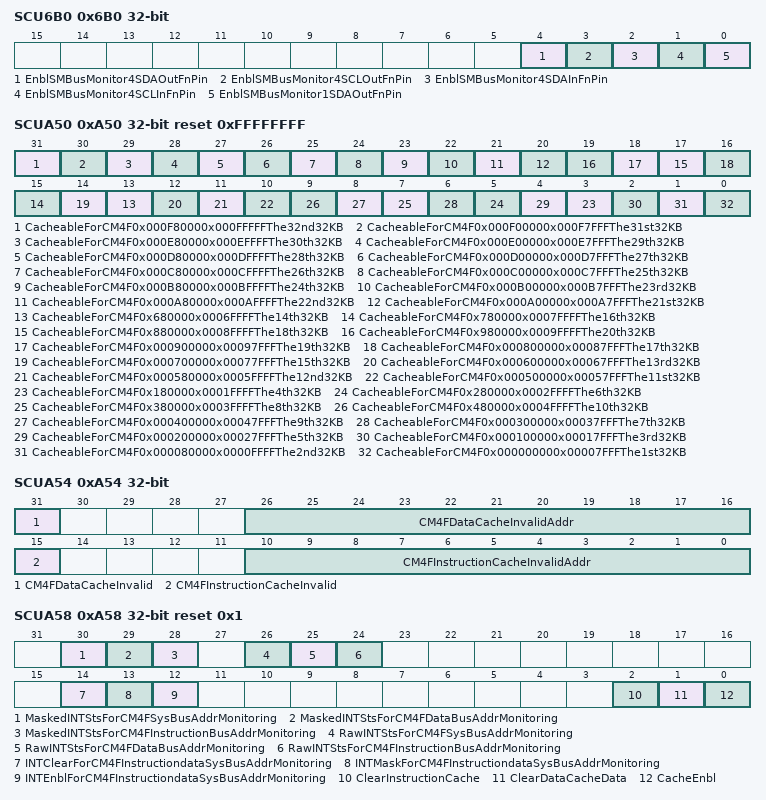
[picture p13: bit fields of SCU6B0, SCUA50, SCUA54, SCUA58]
0x6B0 SCU6B0 — Multi-function Pin Control \#25
  [4] EnblSMBusMonitor4SDAOutFnPin — Enable SMBus Monitor 4 SDA Out function pin
  [3] EnblSMBusMonitor4SCLOutFnPin — Enable SMBus Monitor 4 SCL Out function pin
  [2] EnblSMBusMonitor4SDAInFnPin — Enable SMBus Monitor 4 SDA In function pin
  [1] EnblSMBusMonitor4SCLInFnPin — Enable SMBus Monitor 4 SCL In function pin
  [0] EnblSMBusMonitor1SDAOutFnPin — Enable SMBus Monitor 1 SDA Out function pin
0x6B8 SCU6B8 reset not defined — Multi-function Pin Control \#27
0x6D0 SCU6D0 reset not defined — Multi-function Pin Control \#29
0x6D4 SCU6D4 reset not defined — Multi-function Pin Control \#30
0xA14 SCUA14 — CM4F Memory Base Address Register
  [31:0] SRAMBaseAddrForCM4F — SRAM base address for CM4F
0xA18 SCUA18 reset 0x20000000 — CM4F Instruction Memory Address Limit Register
  [31:0] TheUpperBoundSRAMBaseAddrForCM4FInstruction — The upper bound SRAM base address for CM4F instruction
0xA1C SCUA1C reset 0x20000000 — CM4F Data Memory Address Limit Register
  [31:0] TheUpperBoundSRAMBaseAddrForCM4FData — The upper bound SRAM base address for CM4F data
0xA50 SCUA50 reset 0xFFFFFFFF — CM4F Cacheable Area Declaration
  [31] CacheableForCM4F0x000F80000x000FFFFFThe32nd32KB, [30] CacheableForCM4F0x000F00000x000F7FFFThe31st32KB, [29] CacheableForCM4F0x000E80000x000EFFFFThe30th32KB, [28] CacheableForCM4F0x000E00000x000E7FFFThe29th32KB, [27] CacheableForCM4F0x000D80000x000DFFFFThe28th32KB, [26] CacheableForCM4F0x000D00000x000D7FFFThe27th32KB, [25] CacheableForCM4F0x000C80000x000CFFFFThe26th32KB, [24] CacheableForCM4F0x000C00000x000C7FFFThe25th32KB, [23] CacheableForCM4F0x000B80000x000BFFFFThe24th32KB, [22] CacheableForCM4F0x000B00000x000B7FFFThe23rd32KB, [21] CacheableForCM4F0x000A80000x000AFFFFThe22nd32KB, [20] CacheableForCM4F0x000A00000x000A7FFFThe21st32KB, [2n+1] CacheableForCM4F{0x80000+0x100000*n}x{n:04}FFFFThe{2n+2}th32KB (n=6..9), [18] CacheableForCM4F0x000900000x00097FFFThe19th32KB, [16] CacheableForCM4F0x000800000x00087FFFThe17th32KB, [14] CacheableForCM4F0x000700000x00077FFFThe15th32KB, [12] CacheableForCM4F0x000600000x00067FFFThe13rd32KB, [11] CacheableForCM4F0x000580000x0005FFFFThe12nd32KB, [10] CacheableForCM4F0x000500000x00057FFFThe11st32KB, [2n+1] CacheableForCM4F{0x80000+0x100000*n}x{n:04}FFFFThe{2n+2}th32KB (n=1..4), [8] CacheableForCM4F0x000400000x00047FFFThe9th32KB, [6] CacheableForCM4F0x000300000x00037FFFThe7th32KB, [4] CacheableForCM4F0x000200000x00027FFFThe5th32KB, [2] CacheableForCM4F0x000100000x00017FFFThe3rd32KB, [1] CacheableForCM4F0x000080000x0000FFFFThe2nd32KB, [0] CacheableForCM4F0x000000000x00007FFFThe1st32KB
0xA54 SCUA54 — CM4F Cache Invalidation Control Register
  [31] CM4FDataCacheInvalid
  [26:16] CM4FDataCacheInvalidAddr — CM4F Data Cache Invalid Address
  [15] CM4FInstructionCacheInvalid
  [10:0] CM4FInstructionCacheInvalidAddr — CM4F Instruction Cache Invalid Address
0xA58 SCUA58 reset 0x1 — CM4F Cache Function Control Register
  [30] MaskedINTStsForCM4FSysBusAddrMonitoring ro — Masked interrupt status for CM4F system bus address monitoring
  [29] MaskedINTStsForCM4FDataBusAddrMonitoring ro — Masked interrupt status for CM4F data bus address monitoring
  [28] MaskedINTStsForCM4FInstructionBusAddrMonitoring ro — Masked interrupt status for CM4F instruction bus address monitoring
  [26] RawINTStsForCM4FSysBusAddrMonitoring ro — Raw interrupt status for CM4F system bus address monitoring
  [25] RawINTStsForCM4FDataBusAddrMonitoring ro — Raw interrupt status for CM4F data bus address monitoring
  [24] RawINTStsForCM4FInstructionBusAddrMonitoring ro — Raw interrupt status for CM4F instruction bus address monitoring
  [14] INTClearForCM4FInstructiondataSysBusAddrMonitoring — Interrupt clear for CM4F instruction/data/system bus address monitoring
  [13] INTMaskForCM4FInstructiondataSysBusAddrMonitoring — Interrupt mask for CM4F instruction/data/system bus address monitoring
  [12] INTEnblForCM4FInstructiondataSysBusAddrMonitoring — Interrupt enable for CM4F instruction/data/system bus address monitoring
  [2] ClearInstructionCache
  [1] ClearDataCacheData
  [0] CacheEnbl — Cache Enable
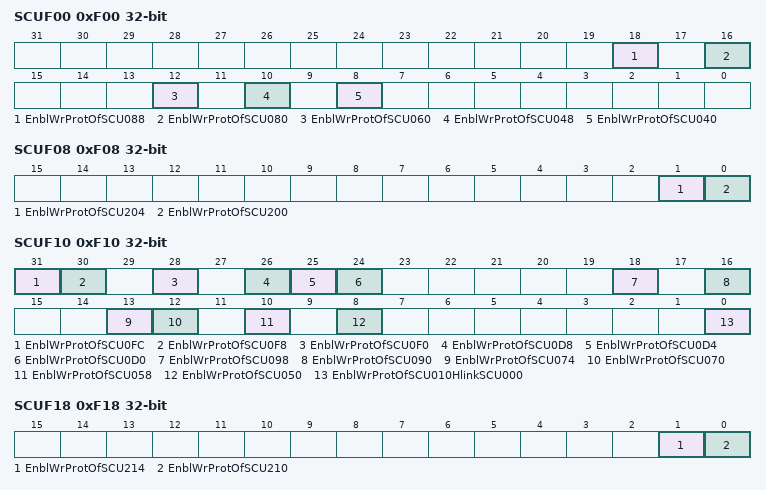
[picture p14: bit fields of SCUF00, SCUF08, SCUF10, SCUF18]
0xF00 SCUF00 — Write Protect Register \#1
  [18] EnblWrProtOfSCU088 — Enable Write Protection of hlinkSCU088
  [16] EnblWrProtOfSCU080 — Enable Write Protection of hlinkSCU080
  [12] EnblWrProtOfSCU060 — Enable Write Protection of hlinkSCU060
  [10] EnblWrProtOfSCU048 — Enable Write Protection of hlinkSCU048
  [8] EnblWrProtOfSCU040 — Enable Write Protection of hlinkSCU040
0xF08 SCUF08 — Write Protect Register \#3
  [1] EnblWrProtOfSCU204 — Enable Write Protection of hlinkSCU204
  [0] EnblWrProtOfSCU200 — Enable Write Protection of hlinkSCU200
0xF10 SCUF10 — Write Protect Register \#5
  [31] EnblWrProtOfSCU0FC — Enable Write Protection of hlinkSCU0FC
  [30] EnblWrProtOfSCU0F8 — Enable Write Protection of hlinkSCU0F8
  [28] EnblWrProtOfSCU0F0 — Enable Write Protection of hlinkSCU0F0
  [26] EnblWrProtOfSCU0D8 — Enable Write Protection of hlinkSCU0D8
  [25] EnblWrProtOfSCU0D4 — Enable Write Protection of hlinkSCU0D4
  [24] EnblWrProtOfSCU0D0 — Enable Write Protection of hlinkSCU0D0
  [18] EnblWrProtOfSCU098 — Enable Write Protection of hlinkSCU098
  [16] EnblWrProtOfSCU090 — Enable Write Protection of hlinkSCU090
  [13] EnblWrProtOfSCU074 — Enable Write Protection of hlinkSCU074
  [12] EnblWrProtOfSCU070 — Enable Write Protection of hlinkSCU070
  [10] EnblWrProtOfSCU058 — Enable Write Protection of hlinkSCU058
  [8] EnblWrProtOfSCU050 — Enable Write Protection of hlinkSCU050
  [0] EnblWrProtOfSCU010HlinkSCU000 — Enable Write Protection of hlinkSCU010 hlinkSCU000
0xF18 SCUF18 — Write Protect Register \#7
  [1] EnblWrProtOfSCU214 — Enable Write Protection of hlinkSCU214
  [0] EnblWrProtOfSCU210 — Enable Write Protection of hlinkSCU210
0xF1C SCUF1C — Write Protect Register \#8
  [7] EnblWrProtOfSCU33C — Enable Write Protection of hlinkSCU33C
  [6] EnblWrProtOfSCU338 — Enable Write Protection of hlinkSCU338
  [5] EnblWrProtOfSCU334 — Enable Write Protection of hlinkSCU334
  [4] EnblWrProtOfSCU330 — Enable Write Protection of hlinkSCU330
  [1] EnblWrProtOfSCU314 — Enable Write Protection of hlinkSCU314
  [0] EnblWrProtOfSCU310 — Enable Write Protection of hlinkSCU310
0xF30 SCUF30 — Write Protect Register \#13
  [26] EnblWrProtOfSCU4D8 — Enable Write Protection of hlinkSCU4D8
  [25] EnblWrProtOfSCU4D4 — Enable Write Protection of hlinkSCU4D4
  [24] EnblWrProtOfSCU4D0 — Enable Write Protection of hlinkSCU4D0
  [23] EnblWrProtOfSCU4BC — Enable Write Protection of hlinkSCU4BC
  [22] EnblWrProtOfSCU4B8 — Enable Write Protection of hlinkSCU4B8
  [21] EnblWrProtOfSCU4B4 — Enable Write Protection of hlinkSCU4B4
  [20] EnblWrProtOfSCU4B0 — Enable Write Protection of hlinkSCU4B0
  [10] EnblWrProtOfSCU458 — Enable Write Protection of hlinkSCU458
  [9] EnblWrProtOfSCU454 — Enable Write Protection of hlinkSCU454
  [8] EnblWrProtOfSCU450 — Enable Write Protection of hlinkSCU450
  [6] EnblWrProtOfSCU438 — Enable Write Protection of hlinkSCU438
  [5] EnblWrProtOfSCU434 — Enable Write Protection of hlinkSCU434
  [4] EnblWrProtOfSCU430 — Enable Write Protection of hlinkSCU430
  [3] EnblWrProtOfSCU41C — Enable Write Protection of hlinkSCU41C
  [2] EnblWrProtOfSCU418 — Enable Write Protection of hlinkSCU418
  [1] EnblWrProtOfSCU414 — Enable Write Protection of hlinkSCU414
  [0] EnblWrProtOfSCU410 — Enable Write Protection of hlinkSCU410
0xF34 SCUF34 — Write Protect Register \#14
  [16] EnblWrProtOfSCU590 — Enable Write Protection of hlinkSCU590
  [8] EnblWrProtOfSCU550 — Enable Write Protection of hlinkSCU550
  [4] EnblWrProtOfSCU530 — Enable Write Protection of hlinkSCU530
  [2] EnblWrProtOfSCU518 — Enable Write Protection of hlinkSCU518
  [1] EnblWrProtOfSCU514 — Enable Write Protection of hlinkSCU514
  [0] EnblWrProtOfSCU510 — Enable Write Protection of hlinkSCU510
0xF38 SCUF38 — Write Protect Register \#15
  [25] EnblWrProtOfSCU6D4 — Enable Write Protection of hlinkSCU6D4
  [24] EnblWrProtOfSCU6D0 — Enable Write Protection of hlinkSCU6D0
  [22] EnblWrProtOfSCU6B8 — Enable Write Protection of hlinkSCU6B8
  [20] EnblWrProtOfSCU6B0 — Enable Write Protection of hlinkSCU6B0
  [19] EnblWrProtOfSCU69C — Enable Write Protection of hlinkSCU69C
  [18] EnblWrProtOfSCU698 — Enable Write Protection of hlinkSCU698
  [17] EnblWrProtOfSCU694 — Enable Write Protection of hlinkSCU694
  [16] EnblWrProtOfSCU690 — Enable Write Protection of hlinkSCU690
  [8] EnblWrProtOfSCU650 — Enable Write Protection of hlinkSCU650
  [6] EnblWrProtOfSCU638 — Enable Write Protection of hlinkSCU638
  [5] EnblWrProtOfSCU634 — Enable Write Protection of hlinkSCU634
  [4] EnblWrProtOfSCU630 — Enable Write Protection of hlinkSCU630
  [3] EnblWrProtOfSCU61C — Enable Write Protection of hlinkSCU61C
  [2] EnblWrProtOfSCU618 — Enable Write Protection of hlinkSCU618
  [1] EnblWrProtOfSCU614 — Enable Write Protection of hlinkSCU614
  [0] EnblWrProtOfSCU610 — Enable Write Protection of hlinkSCU610
0xF50 SCUF50 — Write Protect Register \#21
  [15] EnblWrProtOfSCU87C — Enable Write Protection of hlinkSCU87C
  [14] EnblWrProtOfSCU878 — Enable Write Protection of hlinkSCU878
  [13] EnblWrProtOfSCU874 — Enable Write Protection of hlinkSCU874
  [12] EnblWrProtOfSCU870 — Enable Write Protection of hlinkSCU870
  [11] EnblWrProtOfSCU85C — Enable Write Protection of hlinkSCU85C
  [10] EnblWrProtOfSCU858 — Enable Write Protection of hlinkSCU858
  [9] EnblWrProtOfSCU854 — Enable Write Protection of hlinkSCU854
  [8] EnblWrProtOfSCU850 — Enable Write Protection of hlinkSCU850
  [5] EnblWrProtOfSCU834 — Enable Write Protection of hlinkSCU834
  [4] EnblWrProtOfSCU830 — Enable Write Protection of hlinkSCU830
0xF58 SCUF58 — Write Protect Register \#23
  [10] EnblWrProtOfSCUA58 — Enable Write Protection of hlinkSCUA58
  [9] EnblWrProtOfSCUA54 — Enable Write Protection of hlinkSCUA54
  [8] EnblWrProtOfSCUA50 — Enable Write Protection of hlinkSCUA50
  [3] EnblWrProtOfSCUA1C — Enable Write Protection of hlinkSCUA1C
  [2] EnblWrProtOfSCUA18 — Enable Write Protection of hlinkSCUA18
  [1] EnblWrProtOfSCUA14 — Enable Write Protection of hlinkSCUA14
0xF6C SCUF6C — Write Protect Register \#28
  [31] EnblWrProtOfSCUFEC — Enable Write Protection of hlinkSCUFEC
  [18] EnblWrProtOfSCUF88 — Enable Write Protection of hlinkSCUF88
  [16] EnblWrProtOfSCUF80 — Enable Write Protection of hlinkSCUF80
0xF7C SCUF7C — Write Protect Register \#32
  [31] EnblWrProtOfSCUFFC — Enable Write Protection of hlinkSCUFFC
  [25] EnblWrProtOfSCUFD4 — Enable Write Protection of hlinkSCUFD4
  [24] EnblWrProtOfSCUFD0 — Enable Write Protection of hlinkSCUFD0
  [23] EnblWrProtOfSCUFBC — Enable Write Protection of hlinkSCUFBC
  [22] EnblWrProtOfSCUFB8 — Enable Write Protection of hlinkSCUFB8
  [21] EnblWrProtOfSCUFB4 — Enable Write Protection of hlinkSCUFB4
  [20] EnblWrProtOfSCUFB0 — Enable Write Protection of hlinkSCUFB0
  [19] EnblWrProtOfSCUF9C — Enable Write Protection of hlinkSCUF9C
  [18] EnblWrProtOfSCUF98 — Enable Write Protection of hlinkSCUF98
  [16] EnblWrProtOfSCUF90 — Enable Write Protection of hlinkSCUF90
0xF80 SCUF80 (reset mask 0x51100) — Reset Source Control Register \#1
  [18] EnblARMRSTNAsRstSrcOfHlinkSCU088 — Enable hlinkARMRSTN as reset source of hlinkSCU088
  [16] EnblARMRSTNAsRstSrcOfHlinkSCU080 — Enable hlinkARMRSTN as reset source of hlinkSCU080
  [12] EnblARMRSTNAsRstSrcOfHlinkSCU060 — Enable hlinkARMRSTN as reset source of hlinkSCU060
  [10] EnblARMRSTNAsRstSrcOfHlinkSCU048 — Enable hlinkARMRSTN as reset source of hlinkSCU048
  [8] EnblARMRSTNAsRstSrcOfHlinkSCU040 — Enable hlinkARMRSTN as reset source of hlinkSCU040
0xF88 SCUF88 — Reset Source Control Register \#3
  [1] EnblARMRSTNAsRstSrcOfHlinkSCU204 — Enable hlinkARMRSTN as reset source of hlinkSCU204
  [0] EnblARMRSTNAsRstSrcOfHlinkSCU200 — Enable hlinkARMRSTN as reset source of hlinkSCU200
0xF90 SCUF90 — Reset Source Control Register \#5
  [31] EnblARMRSTNAsRstSrcOfHlinkSCU0FC — Enable hlinkARMRSTN as reset source of hlinkSCU0FC
  [26] EnblARMRSTNAsRstSrcOfHlinkSCU0D8 — Enable hlinkARMRSTN as reset source of hlinkSCU0D8
  [25] EnblARMRSTNAsRstSrcOfHlinkSCU0D4 — Enable hlinkARMRSTN as reset source of hlinkSCU0D4
  [24] EnblARMRSTNAsRstSrcOfHlinkSCU0D0 — Enable hlinkARMRSTN as reset source of hlinkSCU0D0
  [17] EnblARMRSTNAsRstSrcOfHlinkSCU094 — Enable hlinkARMRSTN as reset source of hlinkSCU094
  [16] EnblARMRSTNAsRstSrcOfHlinkSCU090 — Enable hlinkARMRSTN as reset source of hlinkSCU090
  [13] EnblARMRSTNAsRstSrcOfHlinkSCU074 — Enable hlinkARMRSTN as reset source of hlinkSCU074
  [12] EnblARMRSTNAsRstSrcOfHlinkSCU070 — Enable hlinkARMRSTN as reset source of hlinkSCU070
  [8] EnblARMRSTNAsRstSrcOfHlinkSCU050 — Enable hlinkARMRSTN as reset source of hlinkSCU050
  [0] EnblARMRSTNAsRstSrcOfHlinkSCU010HlinkSCU000 — Enable hlinkARMRSTN as reset source of hlinkSCU010 hlinkSCU000
0xF98 SCUF98 — Reset Source Control Register \#7
  [1] EnblARMRSTNAsRstSrcOfHlinkSCU214 — Enable hlinkARMRSTN as reset source of hlinkSCU214
  [0] EnblARMRSTNAsRstSrcOfHlinkSCU210 — Enable hlinkARMRSTN as reset source of hlinkSCU210
0xF9C SCUF9C — Reset Source Control Register \#8
  [7] EnblARMRSTNAsRstSrcOfHlinkSCU33C — Enable hlinkARMRSTN as reset source of hlinkSCU33C
  [6] EnblARMRSTNAsRstSrcOfHlinkSCU338 — Enable hlinkARMRSTN as reset source of hlinkSCU338
  [5] EnblARMRSTNAsRstSrcOfHlinkSCU334 — Enable hlinkARMRSTN as reset source of hlinkSCU334
  [4] EnblARMRSTNAsRstSrcOfHlinkSCU330 — Enable hlinkARMRSTN as reset source of hlinkSCU330
  [1] EnblARMRSTNAsRstSrcOfHlinkSCU314 — Enable hlinkARMRSTN as reset source of hlinkSCU314
  [0] EnblARMRSTNAsRstSrcOfHlinkSCU310 — Enable hlinkARMRSTN as reset source of hlinkSCU310
0xFB0 SCUFB0 — Reset Source Control Register \#13
  [29] EnblARMRSTNAsRstSrcOfHlinkSCU4F4 — Enable hlinkARMRSTN as reset source of hlinkSCU4F4
  [28] EnblARMRSTNAsRstSrcOfHlinkSCU4F0 — Enable hlinkARMRSTN as reset source of hlinkSCU4F0
  [26] EnblARMRSTNAsRstSrcOfHlinkSCU4D8 — Enable hlinkARMRSTN as reset source of hlinkSCU4D8
  [25] EnblARMRSTNAsRstSrcOfHlinkSCU4D4 — Enable hlinkARMRSTN as reset source of hlinkSCU4D4
  [24] EnblARMRSTNAsRstSrcOfHlinkSCU4D0 — Enable hlinkARMRSTN as reset source of hlinkSCU4D0
  [23] EnblARMRSTNAsRstSrcOfHlinkSCU4BC — Enable hlinkARMRSTN as reset source of hlinkSCU4BC
  [22] EnblARMRSTNAsRstSrcOfHlinkSCU4B8 — Enable hlinkARMRSTN as reset source of hlinkSCU4B8
  [21] EnblARMRSTNAsRstSrcOfHlinkSCU4B4 — Enable hlinkARMRSTN as reset source of hlinkSCU4B4
  [20] EnblARMRSTNAsRstSrcOfHlinkSCU4B0 — Enable hlinkARMRSTN as reset source of hlinkSCU4B0
  [10] EnblARMRSTNAsRstSrcOfHlinkSCU458 — Enable hlinkARMRSTN as reset source of hlinkSCU458
  [9] EnblARMRSTNAsRstSrcOfHlinkSCU454 — Enable hlinkARMRSTN as reset source of hlinkSCU454
  [8] EnblARMRSTNAsRstSrcOfHlinkSCU450 — Enable hlinkARMRSTN as reset source of hlinkSCU450
  [6] EnblARMRSTNAsRstSrcOfHlinkSCU438 — Enable hlinkARMRSTN as reset source of hlinkSCU438
  [5] EnblARMRSTNAsRstSrcOfHlinkSCU434 — Enable hlinkARMRSTN as reset source of hlinkSCU434
  [4] EnblARMRSTNAsRstSrcOfHlinkSCU430 — Enable hlinkARMRSTN as reset source of hlinkSCU430
  [3] EnblARMRSTNAsRstSrcOfHlinkSCU41C — Enable hlinkARMRSTN as reset source of hlinkSCU41C
  [2] EnblARMRSTNAsRstSrcOfHlinkSCU418 — Enable hlinkARMRSTN as reset source of hlinkSCU418
  [1] EnblARMRSTNAsRstSrcOfHlinkSCU414 — Enable hlinkARMRSTN as reset source of hlinkSCU414
  [0] EnblARMRSTNAsRstSrcOfHlinkSCU410 — Enable hlinkARMRSTN as reset source of hlinkSCU410
0xFB4 SCUFB4 — Reset Source Control Register \#14
  [23] EnblARMRSTNAsRstSrcOfHlinkSCU5BC — Enable hlinkARMRSTN as reset source of hlinkSCU5BC
  [22] EnblARMRSTNAsRstSrcOfHlinkSCU5B8 — Enable hlinkARMRSTN as reset source of hlinkSCU5B8
  [21] EnblARMRSTNAsRstSrcOfHlinkSCU5B4 — Enable hlinkARMRSTN as reset source of hlinkSCU5B4
  [20] EnblARMRSTNAsRstSrcOfHlinkSCU5B0 — Enable hlinkARMRSTN as reset source of hlinkSCU5B0
  [16] EnblARMRSTNAsRstSrcOfHlinkSCU590 — Enable hlinkARMRSTN as reset source of hlinkSCU590
  [8] EnblARMRSTNAsRstSrcOfHlinkSCU550 — Enable hlinkARMRSTN as reset source of hlinkSCU550
  [4] EnblARMRSTNAsRstSrcOfHlinkSCU530 — Enable hlinkARMRSTN as reset source of hlinkSCU530
  [2] EnblARMRSTNAsRstSrcOfHlinkSCU518 — Enable hlinkARMRSTN as reset source of hlinkSCU518
  [1] EnblARMRSTNAsRstSrcOfHlinkSCU514 — Enable hlinkARMRSTN as reset source of hlinkSCU514
  [0] EnblARMRSTNAsRstSrcOfHlinkSCU510 — Enable hlinkARMRSTN as reset source of hlinkSCU510
0xFB8 SCUFB8 — Reset Source Control Register \#15
  [25] EnblARMRSTNAsRstSrcOfHlinkSCU6D4 — Enable hlinkARMRSTN as reset source of hlinkSCU6D4
  [24] EnblARMRSTNAsRstSrcOfHlinkSCU6D0 — Enable hlinkARMRSTN as reset source of hlinkSCU6D0
  [22] EnblARMRSTNAsRstSrcOfHlinkSCU6B8 — Enable hlinkARMRSTN as reset source of hlinkSCU6B8
  [20] EnblARMRSTNAsRstSrcOfHlinkSCU6B0 — Enable hlinkARMRSTN as reset source of hlinkSCU6B0
  [19] EnblARMRSTNAsRstSrcOfHlinkSCU69C — Enable hlinkARMRSTN as reset source of hlinkSCU69C
  [18] EnblARMRSTNAsRstSrcOfHlinkSCU698 — Enable hlinkARMRSTN as reset source of hlinkSCU698
  [17] EnblARMRSTNAsRstSrcOfHlinkSCU694 — Enable hlinkARMRSTN as reset source of hlinkSCU694
  [16] EnblARMRSTNAsRstSrcOfHlinkSCU690 — Enable hlinkARMRSTN as reset source of hlinkSCU690
  [8] EnblARMRSTNAsRstSrcOfHlinkSCU650 — Enable hlinkARMRSTN as reset source of hlinkSCU650
  [6] EnblARMRSTNAsRstSrcOfHlinkSCU638 — Enable hlinkARMRSTN as reset source of hlinkSCU638
  [5] EnblARMRSTNAsRstSrcOfHlinkSCU634 — Enable hlinkARMRSTN as reset source of hlinkSCU634
  [4] EnblARMRSTNAsRstSrcOfHlinkSCU630 — Enable hlinkARMRSTN as reset source of hlinkSCU630
  [3] EnblARMRSTNAsRstSrcOfHlinkSCU61C — Enable hlinkARMRSTN as reset source of hlinkSCU61C
  [2] EnblARMRSTNAsRstSrcOfHlinkSCU618 — Enable hlinkARMRSTN as reset source of hlinkSCU618
  [1] EnblARMRSTNAsRstSrcOfHlinkSCU614 — Enable hlinkARMRSTN as reset source of hlinkSCU614
  [0] EnblARMRSTNAsRstSrcOfHlinkSCU610 — Enable hlinkARMRSTN as reset source of hlinkSCU610
0xFD0 SCUFD0 — Reset Source Control Register \#21
  [15] EnblARMRSTNAsRstSrcOfHlinkSCU87C — Enable hlinkARMRSTN as reset source of hlinkSCU87C
  [14] EnblARMRSTNAsRstSrcOfHlinkSCU878 — Enable hlinkARMRSTN as reset source of hlinkSCU878
  [13] EnblARMRSTNAsRstSrcOfHlinkSCU874 — Enable hlinkARMRSTN as reset source of hlinkSCU874
  [12] EnblARMRSTNAsRstSrcOfHlinkSCU870 — Enable hlinkARMRSTN as reset source of hlinkSCU870
  [11] EnblARMRSTNAsRstSrcOfHlinkSCU85C — Enable hlinkARMRSTN as reset source of hlinkSCU85C
  [10] EnblARMRSTNAsRstSrcOfHlinkSCU858 — Enable hlinkARMRSTN as reset source of hlinkSCU858
  [9] EnblARMRSTNAsRstSrcOfHlinkSCU854 — Enable hlinkARMRSTN as reset source of hlinkSCU854
  [8] EnblARMRSTNAsRstSrcOfHlinkSCU850 — Enable hlinkARMRSTN as reset source of hlinkSCU850
  [5] EnblARMRSTNAsRstSrcOfHlinkSCU834 — Enable hlinkARMRSTN as reset source of hlinkSCU834
  [4] EnblARMRSTNAsRstSrcOfHlinkSCU830 — Enable hlinkARMRSTN as reset source of hlinkSCU830
0xFEC SCUFEC — Reset Source Control Register \#28
  [15] EnblARMRSTNAsRstSrcOfHlinkSCUF6C — Enable hlinkARMRSTN as reset source of hlinkSCUF6C
  [2] EnblARMRSTNAsRstSrcOfHlinkSCUF08 — Enable hlinkARMRSTN as reset source of hlinkSCUF08
  [0] EnblARMRSTNAsRstSrcOfHlinkSCUF00 — Enable hlinkARMRSTN as reset source of hlinkSCUF00
0xFFC SCUFFC (reset mask 0x81FD) — Reset Source Control Register \#32
  [15] EnblARMRSTNAsRstSrcOfHlinkSCUF7C — Enable hlinkARMRSTN as reset source of hlinkSCUF7C
  [10] EnblARMRSTNAsRstSrcOfHlinkSCUF58 — Enable hlinkARMRSTN as reset source of hlinkSCUF58
  [8] EnblARMRSTNAsRstSrcOfHlinkSCUF50 — Enable hlinkARMRSTN as reset source of hlinkSCUF50
  [7] EnblARMRSTNAsRstSrcOfHlinkSCUF3C — Enable hlinkARMRSTN as reset source of hlinkSCUF3C
  [6] EnblARMRSTNAsRstSrcOfHlinkSCUF38 — Enable hlinkARMRSTN as reset source of hlinkSCUF38
  [5] EnblARMRSTNAsRstSrcOfHlinkSCUF34 — Enable hlinkARMRSTN as reset source of hlinkSCUF34
  [4] EnblARMRSTNAsRstSrcOfHlinkSCUF30 — Enable hlinkARMRSTN as reset source of hlinkSCUF30
  [3] EnblARMRSTNAsRstSrcOfHlinkSCUF1C — Enable hlinkARMRSTN as reset source of hlinkSCUF1C
  [2] EnblARMRSTNAsRstSrcOfHlinkSCUF18 — Enable hlinkARMRSTN as reset source of hlinkSCUF18
  [0] EnblARMRSTNAsRstSrcOfHlinkSCUF10 — Enable hlinkARMRSTN as reset source of hlinkSCUF10
